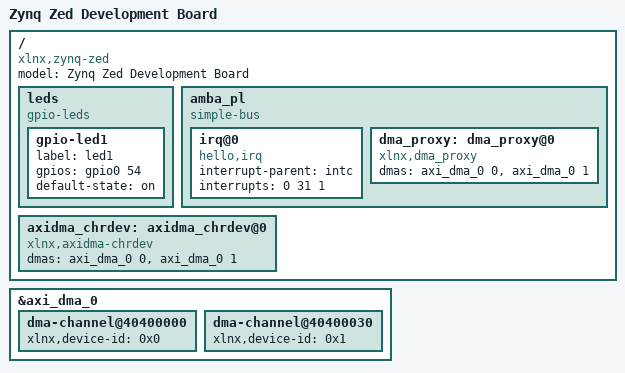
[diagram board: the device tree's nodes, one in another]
/include/ "system-conf.dtsi"
#include <dt-bindings/gpio/gpio.h>

/ {

    model = "Zynq Zed Development Board";
	compatible = "xlnx,zynq-zed", "xlnx,zynq-7000";

    leds {
            compatible = "gpio-leds";

            gpio-led1 {
                    label = "led1";
                    gpios = <&gpio0 54 GPIO_ACTIVE_HIGH>;
                    default-state = "on";
                    /* linux,default-trigger = "heartbeat"; */
            };

    };

    
    amba_pl: amba_pl{
            #address-cells = <1>;
            #size-cells = <1>;
            compatible = "simple-bus";
            ranges;
            irq@0{
                compatible = "hello,irq";
                interrupt-parent = <&intc>;
                interrupts = <0 31 1>;
            };
    };
    

    axidma_chrdev: axidma_chrdev@0 {
        compatible = "xlnx,axidma-chrdev";
        dmas = <&axi_dma_0 0 &axi_dma_0 1>;
        dma-names = "tx_channel","rx_channel";
    };

};

&amba_pl{
    dma_proxy:dma_proxy@0 {
        compatible = "xlnx,dma_proxy";
        dmas =<&axi_dma_0 0 &axi_dma_0 1>;
        dma-names ="dma_proxy_tx","dma_proxy_rx";
    };
};

&axi_dma_0{
    dma-channel@40400000 {
        xlnx,device-id = <0x0>;
    };
    dma-channel@40400030 {
        xlnx,device-id = <0x1>;
    };
};
